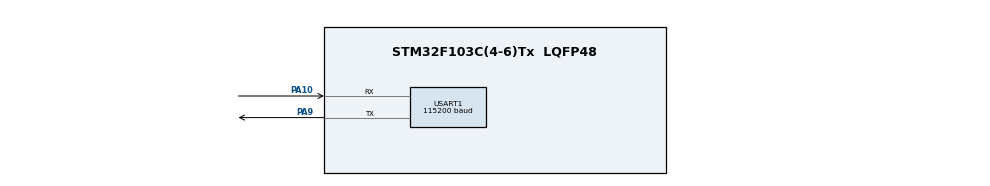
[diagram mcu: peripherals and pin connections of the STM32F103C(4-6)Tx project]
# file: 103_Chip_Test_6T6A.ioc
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Dma.Request0=USART1_TX
Dma.Request1=USART1_RX
Dma.USART1_RX.1.Direction=DMA_PERIPH_TO_MEMORY
Dma.USART1_RX.1.Instance=DMA1_Channel5
Dma.USART1_RX.1.MemDataAlignment=DMA_MDATAALIGN_BYTE
Dma.USART1_RX.1.MemInc=DMA_MINC_ENABLE
Dma.USART1_RX.1.Mode=DMA_NORMAL
Dma.USART1_RX.1.PeriphDataAlignment=DMA_PDATAALIGN_BYTE
Dma.USART1_RX.1.PeriphInc=DMA_PINC_DISABLE
Dma.USART1_RX.1.Priority=DMA_PRIORITY_LOW
Dma.USART1_TX.0.Direction=DMA_MEMORY_TO_PERIPH
Dma.USART1_TX.0.Instance=DMA1_Channel4
Dma.USART1_TX.0.MemDataAlignment=DMA_MDATAALIGN_BYTE
Dma.USART1_TX.0.MemInc=DMA_MINC_ENABLE
Dma.USART1_TX.0.Mode=DMA_NORMAL
Dma.USART1_TX.0.PeriphDataAlignment=DMA_PDATAALIGN_BYTE
Dma.USART1_TX.0.PeriphInc=DMA_PINC_DISABLE
Dma.USART1_TX.0.Priority=DMA_PRIORITY_LOW
Mcu.Family=STM32F1
Mcu.Name=STM32F103C(4-6)Tx
Mcu.Package=LQFP48
NVIC.DMA1_Channel4_IRQn=true\:0\:0\:false\:false\:true\:false\:true\:true
NVIC.DMA1_Channel5_IRQn=true\:0\:0\:false\:false\:true\:false\:true\:true
NVIC.PriorityGroup=NVIC_PRIORITYGROUP_4
PA10.Mode=Asynchronous
PA10.Signal=USART1_RX
PA13.Mode=Serial_Wire
PA13.Signal=SYS_JTMS-SWDIO
PA14.Mode=Serial_Wire
PA14.Signal=SYS_JTCK-SWCLK
PA9.Mode=Asynchronous
PA9.Signal=USART1_TX
ProjectManager.HeapSize=0x200
ProjectManager.StackSize=0x400
ProjectManager.TargetToolchain=STM32CubeIDE
RCC.APB1Freq_Value=8000000
RCC.APB2Freq_Value=8000000
USART1.BaudRate=115200
USART1.VirtualMode=VM_ASYNC
board=custom

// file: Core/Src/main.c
/* USER CODE BEGIN Header */
/**
  ******************************************************************************
  * @file           : main.c
  * @brief          : Main program body
  ******************************************************************************
  * @attention
  *
  * Copyright (c) 2025 STMicroelectronics.
  * All rights reserved.
  *
  * This software is licensed under terms that can be found in the LICENSE file
  * in the root directory of this software component.
  * If no LICENSE file comes with this software, it is provided AS-IS.
  *
  ******************************************************************************
  */
/* USER CODE END Header */
#include "main.h"
#include "dma.h"
#include "usart.h"
#include "gpio.h"

/* USER CODE BEGIN Includes */
#include <stdio.h>
#include <string.h>
#include <stdint.h>
/* USER CODE END Includes */

/* USER CODE BEGIN PD */
#define DBGMCU_IDCODE_ADDR   ((uint32_t)0xE0042000UL)  // DEV_ID[11:0], REV_ID[31:16]
#define FLASH_SIZE_KB_ADDR   ((uint32_t)0x1FFFF7E0UL)  // uint16_t: size in kB
#define UID_BASE_ADDR        ((uint32_t)0x1FFFF7E8UL)  // 96-bit Unique ID (3x32)
/* USER CODE END PD */

/* USER CODE BEGIN PM */
extern UART_HandleTypeDef huart1; // CubeMX in usart.c
/* USER CODE END PM */

/* USER CODE BEGIN PV */
static const char dma_msg[] = "Hello via USART1 DMA TX\r\n";
/* USER CODE END PV */

void SystemClock_Config(void);
/* USER CODE BEGIN PFP */
static inline uint32_t READ_IDCODE(void);
static inline uint16_t READ_FLASH_KB(void);
static inline void     READ_UID(uint32_t uid[3]);
/* USER CODE END PFP */

/* USER CODE BEGIN 0 */
int __io_putchar(int ch) {
  uint8_t c = (uint8_t)ch;
  HAL_UART_Transmit(&huart1, &c, 1, HAL_MAX_DELAY);
  return ch;
}

/* Variante B: _write() für newlib-nano (auskommentieren, wenn syscalls.c existiert) */
int _write(int file, char *ptr, int len) {
  (void)file;
  HAL_UART_Transmit(&huart1, (uint8_t*)ptr, (uint16_t)len, HAL_MAX_DELAY);
  return len;
}

/* Helfer: Register-Leser */
static inline uint32_t READ_IDCODE(void) {
  volatile uint32_t *ID = (uint32_t*)DBGMCU_IDCODE_ADDR;
  return *ID;
}
static inline uint16_t READ_FLASH_KB(void) {
  volatile uint16_t *FS = (uint16_t*)FLASH_SIZE_KB_ADDR;
  return *FS; // kB
}
static inline void READ_UID(uint32_t uid[3]) {
  volatile uint32_t *U = (uint32_t*)UID_BASE_ADDR;
  uid[0] = U[0]; uid[1] = U[1]; uid[2] = U[2];
}

/* Optional: DMA-TX-Callback (Bestätigung) */
void HAL_UART_TxCpltCallback(UART_HandleTypeDef *huart) {
  if (huart->Instance == USART1) {
    const char done[] = "DMA TX complete\r\n";
    HAL_UART_Transmit(&huart1, (uint8_t*)done, (uint16_t)(sizeof(done)-1), 100);
  }
}
/* USER CODE END 0 */

int main(void)
{

  /* MCU Configuration--------------------------------------------------------*/

  /* Reset of all peripherals, Initializes the Flash interface and the Systick. */
  HAL_Init();

  /* Configure the system clock */
  SystemClock_Config();

  /* Initialize all configured peripherals */
  MX_GPIO_Init();
  MX_DMA_Init();
  MX_USART1_UART_Init();
  /* USER CODE BEGIN 2 */
  uint32_t pclk2 = HAL_RCC_GetPCLK2Freq();
  uint32_t brr   = USART1->BRR;
  uint32_t over  = (huart1.Init.OverSampling == UART_OVERSAMPLING_16) ? 16u : 8u;
  printf("Diag: PCLK2=%lu Hz, USART1->BRR=0x%04lX, Over=%lu\r\n",
         (unsigned long)pclk2, (unsigned long)brr, (unsigned long)over);

  // Remap sicher ausschalten (USART1 soll PA9/PA10 nutzen):
  __HAL_RCC_AFIO_CLK_ENABLE();
  __HAL_AFIO_REMAP_USART1_DISABLE();
  	uint32_t idcode = READ_IDCODE();
    uint16_t dev_id = (uint16_t)(idcode & 0x0FFFu);
    uint16_t rev_id = (uint16_t)((idcode >> 16) & 0xFFFFu);
    uint16_t flash_kb = READ_FLASH_KB();
    uint32_t uid[3]; READ_UID(uid);

    printf("\r\n=== Blue Pill ID Check ===\r\n");
    printf("DBGMCU_IDCODE : 0x%08lX  (DEV_ID=0x%03lX, REV_ID=0x%04lX)\r\n",
           (unsigned long)idcode, (unsigned long)dev_id, (unsigned long)rev_id);
    printf("Flash size     : %lu KB\r\n", (unsigned long)flash_kb);
    printf("UID            : %08lX%08lX%08lX\r\n",
           (unsigned long)uid[2], (unsigned long)uid[1], (unsigned long)uid[0]);

    // DMA-TX-Kurztest (USART1 -> DMA1 Channel 4)
    HAL_UART_Transmit_DMA(&huart1, (uint8_t*)dma_msg, (uint16_t)(sizeof(dma_msg)-1));
  /* USER CODE END 2 */

  /* Infinite loop */
  /* USER CODE BEGIN WHILE */
  while (1)
  {
	    HAL_Delay(1000);
    /* USER CODE END WHILE */

  }
}

void SystemClock_Config(void)
{
  RCC_OscInitTypeDef RCC_OscInitStruct = {0};
  RCC_ClkInitTypeDef RCC_ClkInitStruct = {0};

  /** Initializes the RCC Oscillators according to the specified parameters
  * in the RCC_OscInitTypeDef structure.
  */
  RCC_OscInitStruct.OscillatorType = RCC_OSCILLATORTYPE_HSI;
  RCC_OscInitStruct.HSIState = RCC_HSI_ON;
  RCC_OscInitStruct.HSICalibrationValue = RCC_HSICALIBRATION_DEFAULT;
  RCC_OscInitStruct.PLL.PLLState = RCC_PLL_NONE;
  if (HAL_RCC_OscConfig(&RCC_OscInitStruct) != HAL_OK)
  {
    Error_Handler();
  }

  /** Initializes the CPU, AHB and APB buses clocks
  */
  RCC_ClkInitStruct.ClockType = RCC_CLOCKTYPE_HCLK|RCC_CLOCKTYPE_SYSCLK
                              |RCC_CLOCKTYPE_PCLK1|RCC_CLOCKTYPE_PCLK2;
  RCC_ClkInitStruct.SYSCLKSource = RCC_SYSCLKSOURCE_HSI;
  RCC_ClkInitStruct.AHBCLKDivider = RCC_SYSCLK_DIV1;
  RCC_ClkInitStruct.APB1CLKDivider = RCC_HCLK_DIV1;
  RCC_ClkInitStruct.APB2CLKDivider = RCC_HCLK_DIV1;

  if (HAL_RCC_ClockConfig(&RCC_ClkInitStruct, FLASH_LATENCY_0) != HAL_OK)
  {
    Error_Handler();
  }
}

void Error_Handler(void)
{
  __disable_irq();
  while (1)
  {
  }
}
